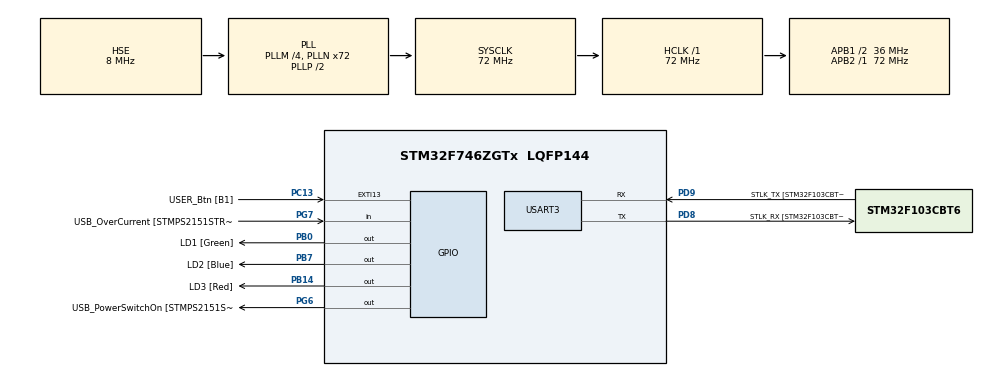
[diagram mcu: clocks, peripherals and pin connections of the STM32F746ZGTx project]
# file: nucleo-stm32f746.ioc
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FREERTOS.Tasks01=defaultTask,0,128,StartDefaultTask,Default,NULL,Dynamic,NULL,NULL;myTask02,-3,128,StartTask02,Default,NULL,Dynamic,NULL,NULL;myTask03,-3,128,StartTask03,Default,NULL,Dynamic,NULL,NULL
Mcu.Family=STM32F7
Mcu.Name=STM32F746ZGTx
Mcu.Package=LQFP144
NVIC.PriorityGroup=NVIC_PRIORITYGROUP_4
NVIC.TIM6_DAC_IRQn=true\:15\:0\:false\:false\:true\:false\:false\:true\:true
NVIC.TimeBase=TIM6_DAC_IRQn
NVIC.TimeBaseIP=TIM6
PA1.GPIO_Mode=GPIO_MODE_AF_PP
PA1.GPIO_PuPd=GPIO_NOPULL
PA1.GPIO_Speed=GPIO_SPEED_FREQ_VERY_HIGH
PA1.Signal=ETH_REF_CLK
PA10.GPIO_Label=USB_ID
PA10.Signal=USB_OTG_FS_ID
PA11.GPIO_Mode=GPIO_MODE_AF_PP
PA11.GPIO_PuPd=GPIO_NOPULL
PA11.GPIO_Speed=GPIO_SPEED_FREQ_VERY_HIGH
PA11.Signal=USB_OTG_FS_DM
PA12.GPIO_Mode=GPIO_MODE_AF_PP
PA12.GPIO_PuPd=GPIO_NOPULL
PA12.GPIO_Speed=GPIO_SPEED_FREQ_VERY_HIGH
PA12.Signal=USB_OTG_FS_DP
PA13.GPIO_Label=TMS
PA13.Mode=Serial_Wire
PA13.Signal=SYS_JTMS-SWDIO
PA14.GPIO_Label=TCK
PA14.Mode=Serial_Wire
PA14.Signal=SYS_JTCK-SWCLK
PA2.GPIO_Mode=GPIO_MODE_AF_PP
PA2.GPIO_PuPd=GPIO_NOPULL
PA2.GPIO_Speed=GPIO_SPEED_FREQ_VERY_HIGH
PA2.Signal=ETH_MDIO
PA7.GPIO_Mode=GPIO_MODE_AF_PP
PA7.GPIO_PuPd=GPIO_NOPULL
PA7.GPIO_Speed=GPIO_SPEED_FREQ_VERY_HIGH
PA7.Signal=ETH_CRS_DV
PA8.GPIO_Label=USB_SOF [TP1]
PA8.Signal=USB_OTG_FS_SOF
PA9.GPIO_Label=USB_VBUS
PA9.Signal=USB_OTG_FS_VBUS
PB0.GPIO_Label=LD1 [Green]
PB0.Signal=GPIO_Output
PB13.GPIO_Mode=GPIO_MODE_AF_PP
PB13.GPIO_PuPd=GPIO_NOPULL
PB13.GPIO_Speed=GPIO_SPEED_FREQ_VERY_HIGH
PB13.Signal=ETH_TXD1
PB14.GPIO_Label=LD3 [Red]
PB14.Signal=GPIO_Output
PB3.GPIO_Label=SW0
PB3.Signal=SYS_JTDO-SWO
PB7.GPIO_Label=LD2 [Blue]
PB7.Signal=GPIO_Output
PC1.GPIO_Mode=GPIO_MODE_AF_PP
PC1.GPIO_PuPd=GPIO_NOPULL
PC1.GPIO_Speed=GPIO_SPEED_FREQ_VERY_HIGH
PC1.Signal=ETH_MDC
PC13.GPIO_Label=USER_Btn [B1]
PC13.Signal=GPXTI13
PC14/OSC32_IN.Mode=LSE-External-Oscillator
PC14/OSC32_IN.Signal=RCC_OSC32_IN
PC15/OSC32_OUT.Mode=LSE-External-Oscillator
PC15/OSC32_OUT.Signal=RCC_OSC32_OUT
PC4.GPIO_Mode=GPIO_MODE_AF_PP
PC4.GPIO_PuPd=GPIO_NOPULL
PC4.GPIO_Speed=GPIO_SPEED_FREQ_VERY_HIGH
PC4.Signal=ETH_RXD0
PC5.GPIO_Mode=GPIO_MODE_AF_PP
PC5.GPIO_PuPd=GPIO_NOPULL
PC5.GPIO_Speed=GPIO_SPEED_FREQ_VERY_HIGH
PC5.Signal=ETH_RXD1
PD8.GPIO_Label=STLK_RX [STM32F103CBT6_PA3]
PD8.Mode=Asynchronous
PD8.Signal=USART3_TX
PD9.GPIO_Label=STLK_TX [STM32F103CBT6_PA2]
PD9.Mode=Asynchronous
PD9.Signal=USART3_RX
PG11.GPIO_Mode=GPIO_MODE_AF_PP
PG11.GPIO_PuPd=GPIO_NOPULL
PG11.GPIO_Speed=GPIO_SPEED_FREQ_VERY_HIGH
PG11.Signal=ETH_TX_EN
PG13.GPIO_Mode=GPIO_MODE_AF_PP
PG13.GPIO_PuPd=GPIO_NOPULL
PG13.GPIO_Speed=GPIO_SPEED_FREQ_VERY_HIGH
PG13.Signal=ETH_TXD0
PG6.GPIO_Label=USB_PowerSwitchOn [STMPS2151STR_EN]
PG6.Signal=GPIO_Output
PG7.GPIO_Label=USB_OverCurrent [STMPS2151STR_FAULT]
PG7.Signal=GPIO_Input
PH0/OSC_IN.GPIO_Label=MCO [STM32F103CBT6_PA8]
PH0/OSC_IN.Mode=HSE-External-Clock-Source
PH0/OSC_IN.Signal=RCC_OSC_IN
PH1/OSC_OUT.Mode=HSE-External-Clock-Source
PH1/OSC_OUT.Signal=RCC_OSC_OUT
ProjectManager.HeapSize=0x200
ProjectManager.StackSize=0x400
ProjectManager.TargetToolchain=STM32CubeIDE
RCC.48MHZClocksFreq_Value=24000000
RCC.AHBFreq_Value=72000000
RCC.APB1CLKDivider=RCC_HCLK_DIV2
RCC.APB1Freq_Value=36000000
RCC.APB1TimFreq_Value=72000000
RCC.APB2Freq_Value=72000000
RCC.APB2TimFreq_Value=72000000
RCC.CortexFreq_Value=72000000
RCC.HCLKFreq_Value=72000000
RCC.HSE_VALUE=8000000
RCC.HSI_VALUE=16000000
RCC.PLLM=4
RCC.PLLMUL=RCC_PLL_MUL9
RCC.PLLN=72
RCC.PLLQ=3
RCC.PLLSourceVirtual=RCC_PLLSOURCE_HSE
RCC.PRESCALERUSB=RCC_USBCLKSOURCE_PLL_DIV1_5
RCC.SYSCLKFreq_VALUE=72000000
RCC.SYSCLKSource=RCC_SYSCLKSOURCE_PLLCLK
RCC.SYSCLKSourceVirtual=RCC_SYSCLKSOURCE_PLLCLK
RCC.USBFreq_Value=48000000
RCC.VCOOutputFreq_Value=144000000
USART3.VirtualMode-Asynchronous=VM_ASYNC
VP_FREERTOS_VS_CMSIS_V1.Mode=CMSIS_V1
VP_SYS_VS_tim6.Mode=TIM6
board=NUCLEO-F746ZG

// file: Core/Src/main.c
/* USER CODE BEGIN Header */
/**
  ******************************************************************************
  * @file           : main.c
  * @brief          : Main program body
  ******************************************************************************
  * @attention
  *
  * Copyright (c) 2023 STMicroelectronics.
  * All rights reserved.
  *
  * This software is licensed under terms that can be found in the LICENSE file
  * in the root directory of this software component.
  * If no LICENSE file comes with this software, it is provided AS-IS.
  *
  ******************************************************************************
  */
/* USER CODE END Header */
#include <stdarg.h>
#include "main.h"
#include "cmsis_os.h"

#include "test_printf.h"

UART_HandleTypeDef huart3;

osThreadId defaultTaskHandle;
osThreadId myTask02Handle;
osThreadId myTask03Handle;
/* USER CODE BEGIN PV */

static void stm32f746_uart_fput(char c);
void target_fput_log(char c);

/* USER CODE END PV */

void SystemClock_Config(void);
static void MX_GPIO_Init(void);
static void MX_USART3_UART_Init(void);
void StartDefaultTask(void const * argument);
void StartTask02(void const * argument);
void StartTask03(void const * argument);

void test_printf(const char *fmt, ...);

int main(void)
{

  /* MCU Configuration--------------------------------------------------------*/

  /* Reset of all peripherals, Initializes the Flash interface and the Systick. */
  HAL_Init();

  /* Configure the system clock */
  SystemClock_Config();

  /* Initialize all configured peripherals */
  MX_GPIO_Init();
  MX_USART3_UART_Init();

  /* Create the thread(s) */
  /* definition and creation of defaultTask */
  osThreadDef(defaultTask, StartDefaultTask, osPriorityNormal, 0, 128);
  defaultTaskHandle = osThreadCreate(osThread(defaultTask), NULL);

  /* definition and creation of myTask02 */
  osThreadDef(myTask02, StartTask02, osPriorityIdle, 0, 128);
  myTask02Handle = osThreadCreate(osThread(myTask02), NULL);

  /* definition and creation of myTask03 */
  osThreadDef(myTask03, StartTask03, osPriorityIdle, 0, 128);
  myTask03Handle = osThreadCreate(osThread(myTask03), NULL);

  /* Start scheduler */
  osKernelStart();

  /* We should never get here as control is now taken by the scheduler */
  /* Infinite loop */
  while (1)
  {

  }
}

void SystemClock_Config(void)
{
  RCC_OscInitTypeDef RCC_OscInitStruct = {0};
  RCC_ClkInitTypeDef RCC_ClkInitStruct = {0};

  /** Configure LSE Drive Capability
  */
  HAL_PWR_EnableBkUpAccess();

  /** Configure the main internal regulator output voltage
  */
  __HAL_RCC_PWR_CLK_ENABLE();
  __HAL_PWR_VOLTAGESCALING_CONFIG(PWR_REGULATOR_VOLTAGE_SCALE3);

  /** Initializes the RCC Oscillators according to the specified parameters
  * in the RCC_OscInitTypeDef structure.
  */
  RCC_OscInitStruct.OscillatorType = RCC_OSCILLATORTYPE_HSE;
  RCC_OscInitStruct.HSEState = RCC_HSE_BYPASS;
  RCC_OscInitStruct.PLL.PLLState = RCC_PLL_ON;
  RCC_OscInitStruct.PLL.PLLSource = RCC_PLLSOURCE_HSE;
  RCC_OscInitStruct.PLL.PLLM = 4;
  RCC_OscInitStruct.PLL.PLLN = 72;
  RCC_OscInitStruct.PLL.PLLP = RCC_PLLP_DIV2;
  RCC_OscInitStruct.PLL.PLLQ = 3;
  if (HAL_RCC_OscConfig(&RCC_OscInitStruct) != HAL_OK)
  {
    Error_Handler();
  }

  /** Initializes the CPU, AHB and APB buses clocks
  */
  RCC_ClkInitStruct.ClockType = RCC_CLOCKTYPE_HCLK|RCC_CLOCKTYPE_SYSCLK
                              |RCC_CLOCKTYPE_PCLK1|RCC_CLOCKTYPE_PCLK2;
  RCC_ClkInitStruct.SYSCLKSource = RCC_SYSCLKSOURCE_PLLCLK;
  RCC_ClkInitStruct.AHBCLKDivider = RCC_SYSCLK_DIV1;
  RCC_ClkInitStruct.APB1CLKDivider = RCC_HCLK_DIV2;
  RCC_ClkInitStruct.APB2CLKDivider = RCC_HCLK_DIV1;

  if (HAL_RCC_ClockConfig(&RCC_ClkInitStruct, FLASH_LATENCY_2) != HAL_OK)
  {
    Error_Handler();
  }
}

static void MX_USART3_UART_Init(void)
{

  huart3.Instance = USART3;
  huart3.Init.BaudRate = 115200;
  huart3.Init.WordLength = UART_WORDLENGTH_8B;
  huart3.Init.StopBits = UART_STOPBITS_1;
  huart3.Init.Parity = UART_PARITY_NONE;
  huart3.Init.Mode = UART_MODE_TX_RX;
  huart3.Init.HwFlowCtl = UART_HWCONTROL_NONE;
  huart3.Init.OverSampling = UART_OVERSAMPLING_16;
  huart3.Init.OneBitSampling = UART_ONE_BIT_SAMPLE_DISABLE;
  huart3.AdvancedInit.AdvFeatureInit = UART_ADVFEATURE_NO_INIT;
  if (HAL_UART_Init(&huart3) != HAL_OK)
  {
    Error_Handler();
  }

}

static void MX_GPIO_Init(void)
{
  GPIO_InitTypeDef GPIO_InitStruct = {0};

  /* GPIO Ports Clock Enable */
  __HAL_RCC_GPIOC_CLK_ENABLE();
  __HAL_RCC_GPIOH_CLK_ENABLE();
  __HAL_RCC_GPIOA_CLK_ENABLE();
  __HAL_RCC_GPIOB_CLK_ENABLE();
  __HAL_RCC_GPIOD_CLK_ENABLE();
  __HAL_RCC_GPIOG_CLK_ENABLE();

  /*Configure GPIO pin Output Level */
  HAL_GPIO_WritePin(GPIOB, LD1_Pin|LD3_Pin|LD2_Pin, GPIO_PIN_RESET);

  /*Configure GPIO pin Output Level */
  HAL_GPIO_WritePin(USB_PowerSwitchOn_GPIO_Port, USB_PowerSwitchOn_Pin, GPIO_PIN_RESET);

  /*Configure GPIO pin : USER_Btn_Pin */
  GPIO_InitStruct.Pin = USER_Btn_Pin;
  GPIO_InitStruct.Mode = GPIO_MODE_IT_RISING;
  GPIO_InitStruct.Pull = GPIO_NOPULL;
  HAL_GPIO_Init(USER_Btn_GPIO_Port, &GPIO_InitStruct);

  /*Configure GPIO pins : PC1 PC4 PC5 */
  GPIO_InitStruct.Pin = GPIO_PIN_1|GPIO_PIN_4|GPIO_PIN_5;
  GPIO_InitStruct.Mode = GPIO_MODE_AF_PP;
  GPIO_InitStruct.Pull = GPIO_NOPULL;
  GPIO_InitStruct.Speed = GPIO_SPEED_FREQ_VERY_HIGH;
  GPIO_InitStruct.Alternate = GPIO_AF11_ETH;
  HAL_GPIO_Init(GPIOC, &GPIO_InitStruct);

  /*Configure GPIO pins : PA1 PA2 PA7 */
  GPIO_InitStruct.Pin = GPIO_PIN_1|GPIO_PIN_2|GPIO_PIN_7;
  GPIO_InitStruct.Mode = GPIO_MODE_AF_PP;
  GPIO_InitStruct.Pull = GPIO_NOPULL;
  GPIO_InitStruct.Speed = GPIO_SPEED_FREQ_VERY_HIGH;
  GPIO_InitStruct.Alternate = GPIO_AF11_ETH;
  HAL_GPIO_Init(GPIOA, &GPIO_InitStruct);

  /*Configure GPIO pins : LD1_Pin LD3_Pin LD2_Pin */
  GPIO_InitStruct.Pin = LD1_Pin|LD3_Pin|LD2_Pin;
  GPIO_InitStruct.Mode = GPIO_MODE_OUTPUT_PP;
  GPIO_InitStruct.Pull = GPIO_NOPULL;
  GPIO_InitStruct.Speed = GPIO_SPEED_FREQ_LOW;
  HAL_GPIO_Init(GPIOB, &GPIO_InitStruct);

  /*Configure GPIO pin : PB13 */
  GPIO_InitStruct.Pin = GPIO_PIN_13;
  GPIO_InitStruct.Mode = GPIO_MODE_AF_PP;
  GPIO_InitStruct.Pull = GPIO_NOPULL;
  GPIO_InitStruct.Speed = GPIO_SPEED_FREQ_VERY_HIGH;
  GPIO_InitStruct.Alternate = GPIO_AF11_ETH;
  HAL_GPIO_Init(GPIOB, &GPIO_InitStruct);

  /*Configure GPIO pin : USB_PowerSwitchOn_Pin */
  GPIO_InitStruct.Pin = USB_PowerSwitchOn_Pin;
  GPIO_InitStruct.Mode = GPIO_MODE_OUTPUT_PP;
  GPIO_InitStruct.Pull = GPIO_NOPULL;
  GPIO_InitStruct.Speed = GPIO_SPEED_FREQ_LOW;
  HAL_GPIO_Init(USB_PowerSwitchOn_GPIO_Port, &GPIO_InitStruct);

  /*Configure GPIO pin : USB_OverCurrent_Pin */
  GPIO_InitStruct.Pin = USB_OverCurrent_Pin;
  GPIO_InitStruct.Mode = GPIO_MODE_INPUT;
  GPIO_InitStruct.Pull = GPIO_NOPULL;
  HAL_GPIO_Init(USB_OverCurrent_GPIO_Port, &GPIO_InitStruct);

  /*Configure GPIO pins : USB_SOF_Pin USB_ID_Pin PA11 PA12 */
  GPIO_InitStruct.Pin = USB_SOF_Pin|USB_ID_Pin|GPIO_PIN_11|GPIO_PIN_12;
  GPIO_InitStruct.Mode = GPIO_MODE_AF_PP;
  GPIO_InitStruct.Pull = GPIO_NOPULL;
  GPIO_InitStruct.Speed = GPIO_SPEED_FREQ_VERY_HIGH;
  GPIO_InitStruct.Alternate = GPIO_AF10_OTG_FS;
  HAL_GPIO_Init(GPIOA, &GPIO_InitStruct);

  /*Configure GPIO pin : USB_VBUS_Pin */
  GPIO_InitStruct.Pin = USB_VBUS_Pin;
  GPIO_InitStruct.Mode = GPIO_MODE_INPUT;
  GPIO_InitStruct.Pull = GPIO_NOPULL;
  HAL_GPIO_Init(USB_VBUS_GPIO_Port, &GPIO_InitStruct);

  /*Configure GPIO pins : PG11 PG13 */
  GPIO_InitStruct.Pin = GPIO_PIN_11|GPIO_PIN_13;
  GPIO_InitStruct.Mode = GPIO_MODE_AF_PP;
  GPIO_InitStruct.Pull = GPIO_NOPULL;
  GPIO_InitStruct.Speed = GPIO_SPEED_FREQ_VERY_HIGH;
  GPIO_InitStruct.Alternate = GPIO_AF11_ETH;
  HAL_GPIO_Init(GPIOG, &GPIO_InitStruct);

}

void StartDefaultTask(void const * argument)
{
  for(;;)
  {
    osDelay(1);
  }
}

void StartTask02(void const * argument)
{
  /* USER CODE BEGIN StartTask02 */
  /* Infinite loop */
  for(;;)
  {

	static int stime = 0;
	//syslog(LOG_NOTICE, "serial\t %d", stime);
    test_printf("serial_debug %d\n", stime);
	osDelay(500);
    stime += 1;
  }
  /* USER CODE END StartTask02 */
}

void StartTask03(void const * argument)
{
  for(;;)
  {
    osDelay(1);
  }
}

void HAL_TIM_PeriodElapsedCallback(TIM_HandleTypeDef *htim)
{
  if (htim->Instance == TIM6) {
    HAL_IncTick();
  }
}

void Error_Handler(void)
{
  __disable_irq();
  while (1)
  {
  }
}

/* 評価用デバッグログ出力 */
void test_printf(const char *fmt, ...)
{
	va_list ap;
	va_start(ap, fmt);
	test_vprintf(target_fput_log, fmt, ap);
	va_end(ap);
}

//::::::::::::基板依存：：：：：：：：：：：：：：：：
/*
 *  SIOポートへの文字出力
 */

static void stm32f746_uart_fput(char c)
{
	/*
	 *  送信できるまでポーリング
	 */
	while((USART3->ISR & Bit7) == 0)  osDelay(1);
	USART3->TDR = (uint32_t)c;
}

void target_fput_log(char c)
{
	if (c == '\n') {
		stm32f746_uart_fput('\r');
	}
	stm32f746_uart_fput(c);
}
